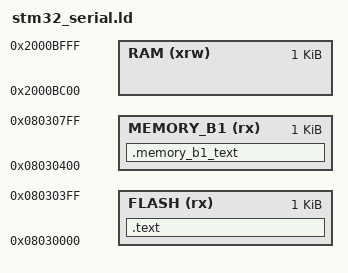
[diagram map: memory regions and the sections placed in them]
/*
*****************************************************************************
**
**  File        : stm32_flash.ld
**
**  Abstract    : Linker script for STM32F103VB Device with
**                128KByte FLASH, 20KByte RAM
**
**                Set heap size, stack size and stack location according
**                to application requirements.
**
**                Set memory bank area and size if external memory is used.
**
**  Target      : STMicroelectronics STM32
**
**  Environment : Atollic TrueSTUDIO(R)
**
**  Distribution: The file is distributed “as is,” without any warranty
**                of any kind.
**
**  (c)Copyright Atollic AB.
**  You may use this file as-is or modify it according to the needs of your
**  project. Distribution of this file (unmodified or modified) is not
**  permitted. Atollic AB permit registered Atollic TrueSTUDIO(R) users the
**  rights to distribute the assembled, compiled & linked contents of this
**  file as part of an application binary file, provided that it is built
**  using the Atollic TrueSTUDIO(R) toolchain.
**
*****************************************************************************
*/

/* Entry Point */
ENTRY(main)



/* Specify the memory areas */
MEMORY
{
  FLASH (rx)      : ORIGIN = 0x08030000, LENGTH = 1K
  RAM (xrw)       : ORIGIN = 0x2000bc00, LENGTH = 1K
  MEMORY_B1 (rx)  : ORIGIN = 0x08030400, LENGTH = 1K
}

/* Define output sections */
SECTIONS
{

  /* The program code and other data goes into FLASH */
  .text :
  {
    . = ALIGN(4);
    *(.text)           /* .text sections (code) */
    *(.text*)          /* .text* sections (code) */
    *(.rodata)         /* .rodata sections (constants, strings, etc.) */
    *(.rodata*)        /* .rodata* sections (constants, strings, etc.) */
    *(.glue_7)         /* glue arm to thumb code */
    *(.glue_7t)        /* glue thumb to arm code */

    KEEP (*(.init))
    KEEP (*(.fini))

    . = ALIGN(4);
    _etext = .;        /* define a global symbols at end of code */
  } >FLASH


  /* MEMORY_bank1 section, code must be located here explicitly            */
  /* Example: extern int foo(void) __attribute__ ((section (".mb1text"))); */
  .memory_b1_text :
  {
    *(.mb1text)        /* .mb1text sections (code) */
    *(.mb1text*)       /* .mb1text* sections (code)  */
    *(.mb1rodata)      /* read-only data (constants) */
    *(.mb1rodata*)
  } >MEMORY_B1

  /* Remove information from the standard libraries */
  /DISCARD/ :
  {
    libc.a ( * )
    libm.a ( * )
    libgcc.a ( * )
  }
}
